# AXI2OCP_MISC register map
Vendor: Texas Instruments
Peripheral module from a debugger description file (folder omap5430_ES2_PUBLIC).
Registers are 32-bit, access per field, reset 0x4 unless marked. A register's access mark holds for its fields unless they carry their own. Offsets are as the file gives them; lines under a group give offsets from that group; [hi:lo] are bit positions; {n}, {i} and the like mark numbered series; 'fields as' and 'values as' point back to an identical list; <NAME> marks a mode.

## AXI2OCP_MISC
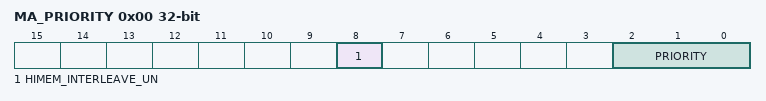
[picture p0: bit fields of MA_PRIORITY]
0x00 MA_PRIORITY — Memory adapter priority register. This register indicates the priority of memory access from MA_MPU to EMIF. This priority is used by EMIF in scheduling MA_MPU access to EMIF. 0x0 is lowest priority and 0x7 is highest priority.
  [8] HIMEM_INTERLEAVE_UN rw
  [2:0] PRIORITY rw — MA_MPU priority value
